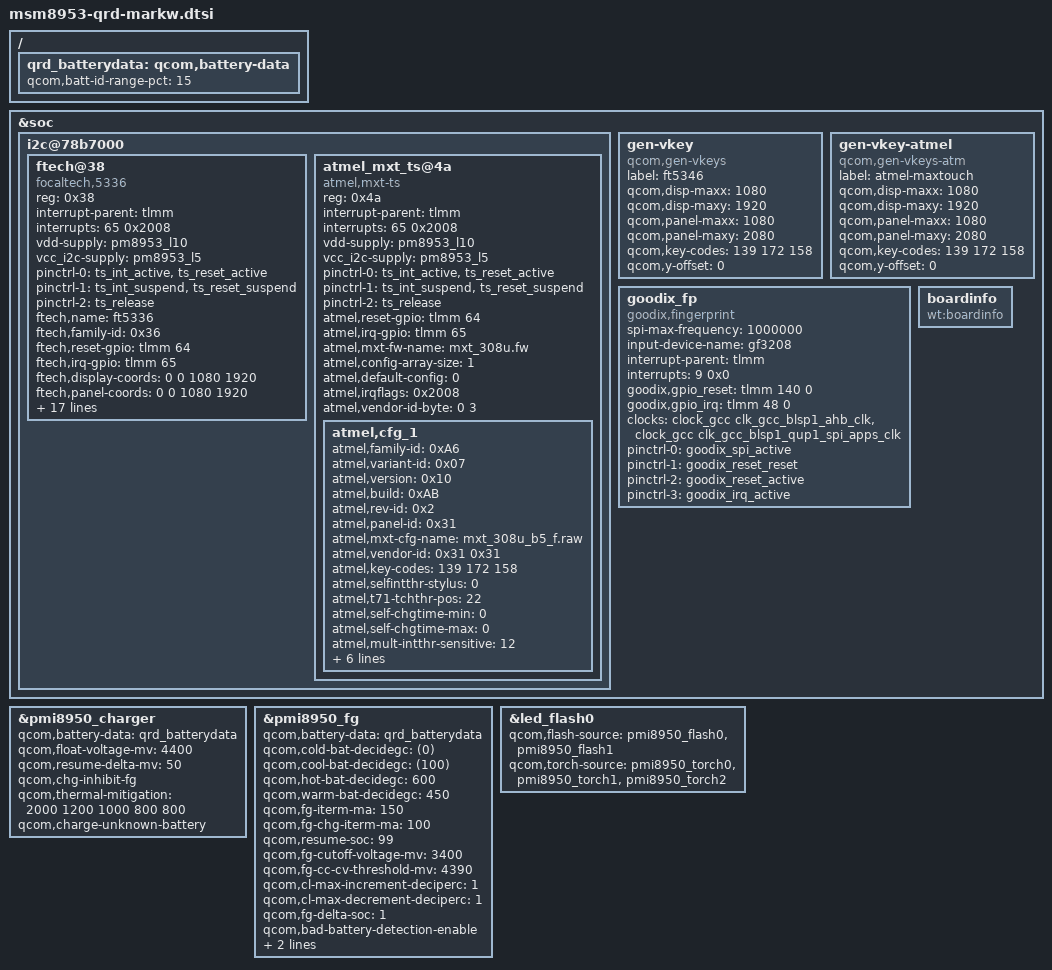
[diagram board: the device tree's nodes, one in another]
/*
 * Copyright (c) 2015-2016, The Linux Foundation. All rights reserved.
 *
 * This program is free software; you can redistribute it and/or modify
 * it under the terms of the GNU General Public License version 2 and
 * only version 2 as published by the Free Software Foundation.
 *
 * This program is distributed in the hope that it will be useful,
 * but WITHOUT ANY WARRANTY; without even the implied warranty of
 * MERCHANTABILITY or FITNESS FOR A PARTICULAR PURPOSE.  See the
 * GNU General Public License for more details.
 */

&soc {
	i2c@78b7000 { /* BLSP1 QUP3 */
		/delete-node/ synaptics@4b;
		ftech@38 {
			compatible = "focaltech,5336";
			reg = <0x38>;
			interrupt-parent = <&tlmm>;
			interrupts = <65 0x2008>;
			vdd-supply = <&pm8953_l10>;
			vcc_i2c-supply = <&pm8953_l5>;
			/* pins used by touchscreen */
			pinctrl-names = "pmx_ts_active","pmx_ts_suspend",
				"pmx_ts_release";
			pinctrl-0 = <&ts_int_active &ts_reset_active>;
			pinctrl-1 = <&ts_int_suspend &ts_reset_suspend>;
			pinctrl-2 = <&ts_release>;
			ftech,name = "ft5336";
			ftech,family-id = <0x36>;
			ftech,reset-gpio = <&tlmm 64 0x00>;
			ftech,irq-gpio = <&tlmm 65 0x2008>;
			ftech,display-coords = <0 0 1080 1920>;
			ftech,panel-coords = <0 0 1080 1920>;
			/*ftech,button-map= <139 102 158>;*/
			ftech,virtual-key1 = <139 180 2000>;/*menu*/
			ftech,virtual-key2 = <172 540 2000>;/*home*/
			ftech,virtual-key3 = <158 900 2000>;/*back*/
			ftech,no-force-update;
			ftech,i2c-pull-up;
			ftech,group-id = <1>;
			ftech,hard-reset-delay-ms = <20>;
			ftech,soft-reset-delay-ms = <200>;
			ftech,num-max-touches = <10>;
			ftech,fw-delay-aa-ms = <30>;
			ftech,fw-delay-55-ms = <30>;
			ftech,fw-upgrade-id1 = <0x79>;
			ftech,fw-upgrade-id2 = <0x18>;
			ftech,fw-delay-readid-ms = <10>;
			ftech,fw-delay-era-flsh-ms = <2000>;
			ftech,fw-auto-cal;
			ftech,ignore-id-check;
		};

		atmel_mxt_ts@4a {
		compatible = "atmel,mxt-ts";
		reg = <0x4a>;
		interrupt-parent = <&tlmm>;
		interrupts = <65 0x2008>;
		vdd-supply = <&pm8953_l10>;
		vcc_i2c-supply = <&pm8953_l5>;
		/* pins used by touchscreen */
		pinctrl-names = "pmx_ts_active","pmx_ts_suspend","pmx_ts_release";
		pinctrl-0 = <&ts_int_active &ts_reset_active>;
		pinctrl-1 = <&ts_int_suspend &ts_reset_suspend>;
		pinctrl-2 = <&ts_release>;
		atmel,reset-gpio = <&tlmm 64 0x0>;
		atmel,irq-gpio = <&tlmm 65 0x2008>;
		atmel,mxt-fw-name = "mxt_308u.fw";
		atmel,config-array-size = <1>;
		atmel,default-config = <0>;
		atmel,irqflags = <0x2008>;
		atmel,vendor-id-byte = /bits/ 8 <0 3>;
		atmel,cfg_1 {
			atmel,family-id = <0xA6>;
			atmel,variant-id = <0x07>;
			atmel,version = <0x10>;
			atmel,build = <0xAB>;
			atmel,rev-id = <0x2>;
			atmel,panel-id = <0x31>;
			atmel,mxt-cfg-name = "mxt_308u_b5_f.raw";
			atmel,vendor-id = /bits/ 8 <0x31 0x31>; /* Biel HW ver 1 */
			atmel,key-codes = <139 172 158>;
			atmel,selfintthr-stylus = <0>;
			atmel,t71-tchthr-pos = <22>;
			atmel,self-chgtime-min = <0>;
			atmel,self-chgtime-max = <0>;
			atmel,mult-intthr-sensitive = <12>;
			atmel,mult-intthr-not-sensitive = <17>;
			atmel,atchthr-sensitive = <6>;
			atmel,mult-tchthr-sensitive = <0>;
			atmel,mult-tchthr-not-sensitive = <0>;
			atmel,wake-up-self-adcx = <16>;
			atmel,support-wakeup-gesture;
			};
		};
	};

	gen-vkey {
		compatible = "qcom,gen-vkeys";
		label = "ft5346";
		qcom,disp-maxx = <1080>;
		qcom,disp-maxy = <1920>;
		qcom,panel-maxx = <1080>;
		qcom,panel-maxy = <2080>;
		qcom,key-codes = <139 172 158>;
		qcom,y-offset = <0>;
	};

	gen-vkey-atmel {
		compatible = "qcom,gen-vkeys-atm";
		label = "atmel-maxtouch";
		qcom,disp-maxx = <1080>;
		qcom,disp-maxy = <1920>;
		qcom,panel-maxx = <1080>;
		qcom,panel-maxy = <2080>;
		qcom,key-codes = <139 172 158>;
		qcom,y-offset = <0>;
	};

	gen-vkey {
		compatible = "qcom,gen-vkeys";
		label = "ft5346";
		qcom,disp-maxx = <1080>;
		qcom,disp-maxy = <1920>;
		qcom,panel-maxx = <1080>;
		qcom,panel-maxy = <2080>;
		qcom,key-codes = <139 172 158>;
		qcom,y-offset = <0>;
	};

	gen-vkey-atmel {
		compatible = "qcom,gen-vkeys-atm";
		label = "atmel-maxtouch";
		qcom,disp-maxx = <1080>;
		qcom,disp-maxy = <1920>;
		qcom,panel-maxx = <1080>;
		qcom,panel-maxy = <2080>;
		qcom,key-codes = <139 172 158>;
		qcom,y-offset = <0>;
	};

	goodix_fp {
		compatible = "goodix,fingerprint";
		 spi-max-frequency = <1000000>;
		input-device-name = "gf3208";
		interrupt-parent = <&tlmm>;
		interrupts = <9 0x0>;

		goodix,gpio_reset    = <&tlmm 140 0>;
		goodix,gpio_irq      = <&tlmm 48 0>;

		clock-names = "iface_clk", "core_clk";
		clocks = <&clock_gcc clk_gcc_blsp1_ahb_clk>,
		<&clock_gcc clk_gcc_blsp1_qup1_spi_apps_clk>;

		pinctrl-names = "goodixfp_spi_active",
			    "goodixfp_reset_reset",
			    "goodixfp_reset_active",
			    "goodixfp_irq_active";

		pinctrl-0 = <&goodix_spi_active>;
		pinctrl-1 = <&goodix_reset_reset>;
		pinctrl-2 = <&goodix_reset_active>;
		pinctrl-3 = <&goodix_irq_active>;
	};

	goodix_fp {
		compatible = "goodix,fingerprint";
		spi-max-frequency = <1000000>;
		input-device-name = "gf3208";
		interrupt-parent = <&tlmm>;
		interrupts = <9 0x0>;

		goodix,gpio_reset    = <&tlmm 140 0>;
		goodix,gpio_irq      = <&tlmm 48 0>;

		clock-names = "iface_clk", "core_clk";
		clocks = <&clock_gcc clk_gcc_blsp1_ahb_clk>,
		<&clock_gcc clk_gcc_blsp1_qup1_spi_apps_clk>;

		pinctrl-names = "goodixfp_spi_active",
				"goodixfp_reset_reset",
				"goodixfp_reset_active",
				"goodixfp_irq_active";

		pinctrl-0 = <&goodix_spi_active>;
		pinctrl-1 = <&goodix_reset_reset>;
		pinctrl-2 = <&goodix_reset_active>;
		pinctrl-3 = <&goodix_irq_active>;
	};

	boardinfo {
		compatible = "wt:boardinfo";
	};
};

/ {
	qrd_batterydata: qcom,battery-data {
		qcom,batt-id-range-pct = <15>;
		#include "MARKW-qrd-Coslight-4v4-4000mah.dtsi"
		#include "MARKW-qrd-Feimaotui-4v4-4000mah.dtsi"
		#include "MARKW-qrd-Default-4v4-4000mah.dtsi"
	};
};

&pmi8950_charger {
	/delete-property/ qcom,chg-led-sw-controls;;
	/delete-property/ qcom,chg-led-support;
	/delete-property/ qcom,external-typec;
	/delete-property/ qcom,typec-psy-name;
	qcom,battery-data = <&qrd_batterydata>;
	qcom,float-voltage-mv = <4400>;
	qcom,resume-delta-mv = <50>;
	qcom,chg-inhibit-fg;
	qcom,thermal-mitigation = <2000 1200 1000 800 800>;
	qcom,charge-unknown-battery;
	status = "okay";
};

&pmi8950_fg {
	qcom,battery-data = <&qrd_batterydata>;
	qcom,cold-bat-decidegc = <(0)>;
	qcom,cool-bat-decidegc = <(100)>;
	qcom,hot-bat-decidegc = <600>;
	qcom,warm-bat-decidegc = <450>;
 	qcom,fg-iterm-ma = <150>;
	qcom,fg-chg-iterm-ma = <100>;
	qcom,resume-soc = <99>;
	qcom,fg-cutoff-voltage-mv = <3400>;
	qcom,fg-cc-cv-threshold-mv = <4390>;
	qcom,cl-max-increment-deciperc = <1>;
	qcom,cl-max-decrement-deciperc = <1>;
	qcom,fg-delta-soc = <1>;
	qcom,bad-battery-detection-enable;
	qcom,hold-soc-while-full;
	qcom,thermal-coefficients = [c2 86 bb 50 cf 37];
};

/delete-node/ &flash_led;

&led_flash0{
	qcom,flash-source = <&pmi8950_flash0 &pmi8950_flash1>;
	qcom,torch-source = <&pmi8950_torch0 &pmi8950_torch1 &pmi8950_torch2>;
};
